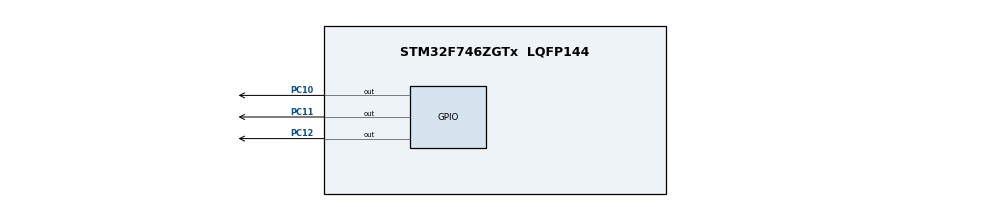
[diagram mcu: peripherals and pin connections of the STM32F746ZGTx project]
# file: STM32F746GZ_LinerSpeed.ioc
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Mcu.Family=STM32F7
PC12.Signal=GPIO_Output
PC11.Signal=GPIO_Output
PC10.Signal=GPIO_Output
ProjectManager.StackSize=0x400
TIM1.Prescaler=16-1
ProjectManager.TargetToolchain=STM32CubeIDE
RCC.USBFreq_Value=96000000
RCC.LSE_VALUE=32768
RCC.HSE_VALUE=25000000
NVIC.TIM1_TRG_COM_TIM11_IRQn=true\:0\:0\:false\:false\:true\:true\:true
board=custom
RCC.VCOOutputFreq_Value=192000000
Mcu.Name=STM32F746ZGTx
VP_TIM1_VS_ClockSourceINT.Mode=Internal
NVIC.TIM1_CC_IRQn=true\:0\:0\:false\:false\:true\:true\:true
Mcu.Package=LQFP144
ProjectManager.HeapSize=0x200
RCC.HSI_VALUE=16000000
NVIC.PriorityGroup=NVIC_PRIORITYGROUP_4
TIM1.Period=0xffff-1

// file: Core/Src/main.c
/* USER CODE BEGIN Header */
/**
  ******************************************************************************
  * @file           : main.c
  * @brief          : Main program body
  ******************************************************************************
  * @attention
  *
  * <h2><center>&copy; Copyright (c) 2021 STMicroelectronics.
  * All rights reserved.</center></h2>
  *
  * This software component is licensed by ST under BSD 3-Clause license,
  * the "License"; You may not use this file except in compliance with the
  * License. You may obtain a copy of the License at:
  *                        opensource.org/licenses/BSD-3-Clause
  *
  ******************************************************************************
  */
/* USER CODE END Header */
#include "main.h"

/* USER CODE BEGIN Includes */
#include <math.h>
/* USER CODE END Includes */

/* USER CODE BEGIN PD */
#define STEPS 1000
/* USER CODE END PD */

TIM_HandleTypeDef htim1;

void SystemClock_Config(void);
static void MX_GPIO_Init(void);
static void MX_TIM1_Init(void);

/* USER CODE BEGIN 0 */
void delay_us (uint16_t us)
{
	__HAL_TIM_SET_COUNTER(&htim1, 0);
	while(__HAL_TIM_GET_COUNTER(&htim1) < us);
}

void constantAccel(){
	int   delays[STEPS];
	float angle = 0.031416;
	float accel = 0.01;
	float c0 = 10000 * sqrt(2 * angle / accel) * 0.67703;
	float lastDelay = 0;
	int   highSpeed = 100;
	for (int i = 0; i < STEPS; i++){
		float d = c0;
		if (i > 0)
			d = lastDelay - (2 * lastDelay) / (4 * i + 1);
		if (d < highSpeed)
			d = highSpeed;
		delays[i] = d;
		lastDelay = d;
	}

	for (int i = 0; i < STEPS; i++) {
		HAL_GPIO_WritePin(GPIOC, GPIO_PIN_12, GPIO_PIN_SET);
		delay_us(delays[i]);
		HAL_GPIO_WritePin(GPIOC, GPIO_PIN_12, GPIO_PIN_RESET);
	}

	for (int i = 0; i < STEPS; i++) {
		HAL_GPIO_WritePin(GPIOC, GPIO_PIN_12, GPIO_PIN_SET);
		delay_us(delays[STEPS-i-1]);
		HAL_GPIO_WritePin(GPIOC, GPIO_PIN_12, GPIO_PIN_RESET);
	}
}
/* USER CODE END 0 */

int main(void)
{

  /* MCU Configuration--------------------------------------------------------*/

  /* Reset of all peripherals, Initializes the Flash interface and the Systick. */
  HAL_Init();

  /* Configure the system clock */
  SystemClock_Config();

  /* Initialize all configured peripherals */
  MX_GPIO_Init();
  MX_TIM1_Init();
  /* USER CODE BEGIN 2 */
  HAL_GPIO_WritePin(GPIOC, GPIO_PIN_10, GPIO_PIN_RESET);
  HAL_TIM_Base_Start_IT(&htim1);
  /* USER CODE END 2 */

  /* Infinite loop */
  while (1)
  {

    /* USER CODE BEGIN 3 */
	  HAL_GPIO_WritePin(GPIOC, GPIO_PIN_11, GPIO_PIN_SET);
	  constantAccel();
	  HAL_GPIO_WritePin(GPIOC, GPIO_PIN_11, GPIO_PIN_RESET);
	  constantAccel();

	  HAL_Delay(3000);
  }
  /* USER CODE END 3 */
}

void SystemClock_Config(void)
{
  RCC_OscInitTypeDef RCC_OscInitStruct = {0};
  RCC_ClkInitTypeDef RCC_ClkInitStruct = {0};

  /** Configure the main internal regulator output voltage
  */
  __HAL_RCC_PWR_CLK_ENABLE();
  __HAL_PWR_VOLTAGESCALING_CONFIG(PWR_REGULATOR_VOLTAGE_SCALE3);
  /** Initializes the RCC Oscillators according to the specified parameters
  * in the RCC_OscInitTypeDef structure.
  */
  RCC_OscInitStruct.OscillatorType = RCC_OSCILLATORTYPE_HSI;
  RCC_OscInitStruct.HSIState = RCC_HSI_ON;
  RCC_OscInitStruct.HSICalibrationValue = RCC_HSICALIBRATION_DEFAULT;
  RCC_OscInitStruct.PLL.PLLState = RCC_PLL_NONE;
  if (HAL_RCC_OscConfig(&RCC_OscInitStruct) != HAL_OK)
  {
    Error_Handler();
  }
  /** Initializes the CPU, AHB and APB buses clocks
  */
  RCC_ClkInitStruct.ClockType = RCC_CLOCKTYPE_HCLK|RCC_CLOCKTYPE_SYSCLK
                              |RCC_CLOCKTYPE_PCLK1|RCC_CLOCKTYPE_PCLK2;
  RCC_ClkInitStruct.SYSCLKSource = RCC_SYSCLKSOURCE_HSI;
  RCC_ClkInitStruct.AHBCLKDivider = RCC_SYSCLK_DIV1;
  RCC_ClkInitStruct.APB1CLKDivider = RCC_HCLK_DIV1;
  RCC_ClkInitStruct.APB2CLKDivider = RCC_HCLK_DIV1;

  if (HAL_RCC_ClockConfig(&RCC_ClkInitStruct, FLASH_LATENCY_0) != HAL_OK)
  {
    Error_Handler();
  }
}

static void MX_TIM1_Init(void)
{

  TIM_ClockConfigTypeDef sClockSourceConfig = {0};
  TIM_MasterConfigTypeDef sMasterConfig = {0};

  htim1.Instance = TIM1;
  htim1.Init.Prescaler = 16-1;
  htim1.Init.CounterMode = TIM_COUNTERMODE_UP;
  htim1.Init.Period = 0xffff-1;
  htim1.Init.ClockDivision = TIM_CLOCKDIVISION_DIV1;
  htim1.Init.RepetitionCounter = 0;
  htim1.Init.AutoReloadPreload = TIM_AUTORELOAD_PRELOAD_DISABLE;
  if (HAL_TIM_Base_Init(&htim1) != HAL_OK)
  {
    Error_Handler();
  }
  sClockSourceConfig.ClockSource = TIM_CLOCKSOURCE_INTERNAL;
  if (HAL_TIM_ConfigClockSource(&htim1, &sClockSourceConfig) != HAL_OK)
  {
    Error_Handler();
  }
  sMasterConfig.MasterOutputTrigger = TIM_TRGO_RESET;
  sMasterConfig.MasterOutputTrigger2 = TIM_TRGO2_RESET;
  sMasterConfig.MasterSlaveMode = TIM_MASTERSLAVEMODE_DISABLE;
  if (HAL_TIMEx_MasterConfigSynchronization(&htim1, &sMasterConfig) != HAL_OK)
  {
    Error_Handler();
  }

}

static void MX_GPIO_Init(void)
{
  GPIO_InitTypeDef GPIO_InitStruct = {0};

  /* GPIO Ports Clock Enable */
  __HAL_RCC_GPIOC_CLK_ENABLE();

  /*Configure GPIO pin Output Level */
  HAL_GPIO_WritePin(GPIOC, GPIO_PIN_10|GPIO_PIN_11|GPIO_PIN_12, GPIO_PIN_RESET);

  /*Configure GPIO pins : PC10 PC11 PC12 */
  GPIO_InitStruct.Pin = GPIO_PIN_10|GPIO_PIN_11|GPIO_PIN_12;
  GPIO_InitStruct.Mode = GPIO_MODE_OUTPUT_PP;
  GPIO_InitStruct.Pull = GPIO_NOPULL;
  GPIO_InitStruct.Speed = GPIO_SPEED_FREQ_LOW;
  HAL_GPIO_Init(GPIOC, &GPIO_InitStruct);

}

void Error_Handler(void)
{
  __disable_irq();
  while (1)
  {
  }
}

/************************ (C) COPYRIGHT STMicroelectronics *****END OF FILE****/
